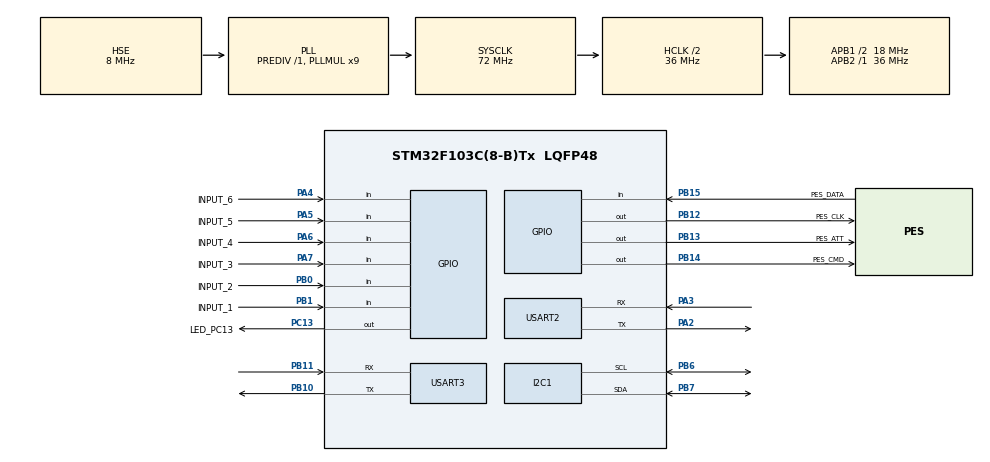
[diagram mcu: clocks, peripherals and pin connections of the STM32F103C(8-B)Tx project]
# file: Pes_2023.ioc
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IWDG.Prescaler=IWDG_PRESCALER_8
IWDG.Reload=2500-1
Mcu.Family=STM32F1
Mcu.Name=STM32F103C(8-B)Tx
Mcu.Package=LQFP48
NVIC.PriorityGroup=NVIC_PRIORITYGROUP_4
NVIC.USART3_IRQn=true\:0\:0\:false\:false\:true\:true\:true\:true
PA13.Mode=Serial_Wire
PA13.Signal=SYS_JTMS-SWDIO
PA14.Mode=Serial_Wire
PA14.Signal=SYS_JTCK-SWCLK
PA2.Mode=Asynchronous
PA2.Signal=USART2_TX
PA3.Mode=Asynchronous
PA3.Signal=USART2_RX
PA4.GPIO_Label=INPUT_6
PA4.GPIO_PuPd=GPIO_PULLUP
PA4.Signal=GPIO_Input
PA5.GPIO_Label=INPUT_5
PA5.GPIO_PuPd=GPIO_PULLUP
PA5.Signal=GPIO_Input
PA6.GPIO_Label=INPUT_4
PA6.GPIO_PuPd=GPIO_PULLUP
PA6.Signal=GPIO_Input
PA7.GPIO_Label=INPUT_3
PA7.GPIO_PuPd=GPIO_PULLUP
PA7.Signal=GPIO_Input
PB0.GPIO_Label=INPUT_2
PB0.GPIO_PuPd=GPIO_PULLUP
PB0.Signal=GPIO_Input
PB1.GPIO_Label=INPUT_1
PB1.GPIO_PuPd=GPIO_PULLUP
PB1.Signal=GPIO_Input
PB10.Mode=Asynchronous
PB10.Signal=USART3_TX
PB11.Mode=Asynchronous
PB11.Signal=USART3_RX
PB12.GPIO_Label=PES_CLK
PB12.GPIO_Speed=GPIO_SPEED_FREQ_MEDIUM
PB12.Signal=GPIO_Output
PB13.GPIO_Label=PES_ATT
PB13.GPIO_Speed=GPIO_SPEED_FREQ_MEDIUM
PB13.Signal=GPIO_Output
PB14.GPIO_Label=PES_CMD
PB14.GPIO_Speed=GPIO_SPEED_FREQ_MEDIUM
PB14.Signal=GPIO_Output
PB15.GPIO_Label=PES_DATA
PB15.GPIO_PuPd=GPIO_PULLUP
PB15.Signal=GPIO_Input
PB6.Mode=I2C
PB6.Signal=I2C1_SCL
PB7.Mode=I2C
PB7.Signal=I2C1_SDA
PC13-TAMPER-RTC.GPIO_Label=LED_PC13
PC13-TAMPER-RTC.Signal=GPIO_Output
PD0-OSC_IN.Mode=HSE-External-Oscillator
PD0-OSC_IN.Signal=RCC_OSC_IN
PD1-OSC_OUT.Mode=HSE-External-Oscillator
PD1-OSC_OUT.Signal=RCC_OSC_OUT
ProjectManager.HeapSize=0x200
ProjectManager.StackSize=0x400
ProjectManager.TargetToolchain=STM32CubeIDE
RCC.AHBCLKDivider=RCC_SYSCLK_DIV2
RCC.AHBFreq_Value=36000000
RCC.APB1CLKDivider=RCC_HCLK_DIV2
RCC.APB1Freq_Value=18000000
RCC.APB1TimFreq_Value=36000000
RCC.APB2Freq_Value=36000000
RCC.APB2TimFreq_Value=36000000
RCC.HCLKFreq_Value=36000000
RCC.PLLMUL=RCC_PLL_MUL9
RCC.PLLSourceVirtual=RCC_PLLSOURCE_HSE
RCC.SYSCLKFreq_VALUE=72000000
RCC.SYSCLKSource=RCC_SYSCLKSOURCE_PLLCLK
RCC.USBFreq_Value=72000000
USART2.VirtualMode=VM_ASYNC
USART3.VirtualMode=VM_ASYNC
VP_IWDG_VS_IWDG.Mode=IWDG_Activate
board=custom

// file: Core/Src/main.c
/* USER CODE BEGIN Header */
/**
  ******************************************************************************
  * @file           : main.c
  * @brief          : Main program body
  ******************************************************************************
  * @attention
  *
  * Copyright (c) 2023 STMicroelectronics.
  * All rights reserved.
  *
  * This software is licensed under terms that can be found in the LICENSE file
  * in the root directory of this software component.
  * If no LICENSE file comes with this software, it is provided AS-IS.
  *
  ******************************************************************************
  */
/* USER CODE END Header */
#include "main.h"

/* USER CODE BEGIN Includes */
#include "../user/main-app.h"
/* USER CODE END Includes */

I2C_HandleTypeDef hi2c1;

IWDG_HandleTypeDef hiwdg;

UART_HandleTypeDef huart2;
UART_HandleTypeDef huart3;

void SystemClock_Config(void);
static void MX_GPIO_Init(void);
static void MX_USART3_UART_Init(void);
static void MX_IWDG_Init(void);
static void MX_USART2_UART_Init(void);
static void MX_I2C1_Init(void);

int main(void)
{

  /* MCU Configuration--------------------------------------------------------*/

  /* Reset of all peripherals, Initializes the Flash interface and the Systick. */
  HAL_Init();

  /* Configure the system clock */
  SystemClock_Config();

  /* Initialize all configured peripherals */
  MX_GPIO_Init();
  MX_USART3_UART_Init();
  MX_IWDG_Init();
  MX_USART2_UART_Init();
  MX_I2C1_Init();
  /* USER CODE BEGIN 2 */
  main_Init();
  /* USER CODE END 2 */

  /* Infinite loop */
  /* USER CODE BEGIN WHILE */
  while (1)
  {
	  main_process();
	  HAL_IWDG_Refresh(&hiwdg);
    /* USER CODE END WHILE */

  }
}

void SystemClock_Config(void)
{
  RCC_OscInitTypeDef RCC_OscInitStruct = {0};
  RCC_ClkInitTypeDef RCC_ClkInitStruct = {0};

  /** Initializes the RCC Oscillators according to the specified parameters
  * in the RCC_OscInitTypeDef structure.
  */
  RCC_OscInitStruct.OscillatorType = RCC_OSCILLATORTYPE_LSI|RCC_OSCILLATORTYPE_HSE;
  RCC_OscInitStruct.HSEState = RCC_HSE_ON;
  RCC_OscInitStruct.HSEPredivValue = RCC_HSE_PREDIV_DIV1;
  RCC_OscInitStruct.HSIState = RCC_HSI_ON;
  RCC_OscInitStruct.LSIState = RCC_LSI_ON;
  RCC_OscInitStruct.PLL.PLLState = RCC_PLL_ON;
  RCC_OscInitStruct.PLL.PLLSource = RCC_PLLSOURCE_HSE;
  RCC_OscInitStruct.PLL.PLLMUL = RCC_PLL_MUL9;
  if (HAL_RCC_OscConfig(&RCC_OscInitStruct) != HAL_OK)
  {
    Error_Handler();
  }

  /** Initializes the CPU, AHB and APB buses clocks
  */
  RCC_ClkInitStruct.ClockType = RCC_CLOCKTYPE_HCLK|RCC_CLOCKTYPE_SYSCLK
                              |RCC_CLOCKTYPE_PCLK1|RCC_CLOCKTYPE_PCLK2;
  RCC_ClkInitStruct.SYSCLKSource = RCC_SYSCLKSOURCE_PLLCLK;
  RCC_ClkInitStruct.AHBCLKDivider = RCC_SYSCLK_DIV2;
  RCC_ClkInitStruct.APB1CLKDivider = RCC_HCLK_DIV2;
  RCC_ClkInitStruct.APB2CLKDivider = RCC_HCLK_DIV1;

  if (HAL_RCC_ClockConfig(&RCC_ClkInitStruct, FLASH_LATENCY_2) != HAL_OK)
  {
    Error_Handler();
  }
}

static void MX_I2C1_Init(void)
{

  hi2c1.Instance = I2C1;
  hi2c1.Init.ClockSpeed = 100000;
  hi2c1.Init.DutyCycle = I2C_DUTYCYCLE_2;
  hi2c1.Init.OwnAddress1 = 0;
  hi2c1.Init.AddressingMode = I2C_ADDRESSINGMODE_7BIT;
  hi2c1.Init.DualAddressMode = I2C_DUALADDRESS_DISABLE;
  hi2c1.Init.OwnAddress2 = 0;
  hi2c1.Init.GeneralCallMode = I2C_GENERALCALL_DISABLE;
  hi2c1.Init.NoStretchMode = I2C_NOSTRETCH_DISABLE;
  if (HAL_I2C_Init(&hi2c1) != HAL_OK)
  {
    Error_Handler();
  }

}

static void MX_IWDG_Init(void)
{

  hiwdg.Instance = IWDG;
  hiwdg.Init.Prescaler = IWDG_PRESCALER_8;
  hiwdg.Init.Reload = 2500-1;
  if (HAL_IWDG_Init(&hiwdg) != HAL_OK)
  {
    Error_Handler();
  }

}

static void MX_USART2_UART_Init(void)
{

  huart2.Instance = USART2;
  huart2.Init.BaudRate = 115200;
  huart2.Init.WordLength = UART_WORDLENGTH_8B;
  huart2.Init.StopBits = UART_STOPBITS_1;
  huart2.Init.Parity = UART_PARITY_NONE;
  huart2.Init.Mode = UART_MODE_TX_RX;
  huart2.Init.HwFlowCtl = UART_HWCONTROL_NONE;
  huart2.Init.OverSampling = UART_OVERSAMPLING_16;
  if (HAL_UART_Init(&huart2) != HAL_OK)
  {
    Error_Handler();
  }

}

static void MX_USART3_UART_Init(void)
{

  huart3.Instance = USART3;
  huart3.Init.BaudRate = 115200;
  huart3.Init.WordLength = UART_WORDLENGTH_8B;
  huart3.Init.StopBits = UART_STOPBITS_1;
  huart3.Init.Parity = UART_PARITY_NONE;
  huart3.Init.Mode = UART_MODE_TX_RX;
  huart3.Init.HwFlowCtl = UART_HWCONTROL_NONE;
  huart3.Init.OverSampling = UART_OVERSAMPLING_16;
  if (HAL_UART_Init(&huart3) != HAL_OK)
  {
    Error_Handler();
  }

}

static void MX_GPIO_Init(void)
{
  GPIO_InitTypeDef GPIO_InitStruct = {0};

  /* GPIO Ports Clock Enable */
  __HAL_RCC_GPIOC_CLK_ENABLE();
  __HAL_RCC_GPIOD_CLK_ENABLE();
  __HAL_RCC_GPIOA_CLK_ENABLE();
  __HAL_RCC_GPIOB_CLK_ENABLE();

  /*Configure GPIO pin Output Level */
  HAL_GPIO_WritePin(LED_PC13_GPIO_Port, LED_PC13_Pin, GPIO_PIN_RESET);

  /*Configure GPIO pin Output Level */
  HAL_GPIO_WritePin(GPIOB, PES_CLK_Pin|PES_ATT_Pin|PES_CMD_Pin, GPIO_PIN_RESET);

  /*Configure GPIO pin : LED_PC13_Pin */
  GPIO_InitStruct.Pin = LED_PC13_Pin;
  GPIO_InitStruct.Mode = GPIO_MODE_OUTPUT_PP;
  GPIO_InitStruct.Pull = GPIO_NOPULL;
  GPIO_InitStruct.Speed = GPIO_SPEED_FREQ_LOW;
  HAL_GPIO_Init(LED_PC13_GPIO_Port, &GPIO_InitStruct);

  /*Configure GPIO pins : INPUT_6_Pin INPUT_5_Pin INPUT_4_Pin INPUT_3_Pin */
  GPIO_InitStruct.Pin = INPUT_6_Pin|INPUT_5_Pin|INPUT_4_Pin|INPUT_3_Pin;
  GPIO_InitStruct.Mode = GPIO_MODE_INPUT;
  GPIO_InitStruct.Pull = GPIO_PULLUP;
  HAL_GPIO_Init(GPIOA, &GPIO_InitStruct);

  /*Configure GPIO pins : INPUT_2_Pin INPUT_1_Pin PES_DATA_Pin */
  GPIO_InitStruct.Pin = INPUT_2_Pin|INPUT_1_Pin|PES_DATA_Pin;
  GPIO_InitStruct.Mode = GPIO_MODE_INPUT;
  GPIO_InitStruct.Pull = GPIO_PULLUP;
  HAL_GPIO_Init(GPIOB, &GPIO_InitStruct);

  /*Configure GPIO pins : PES_CLK_Pin PES_ATT_Pin PES_CMD_Pin */
  GPIO_InitStruct.Pin = PES_CLK_Pin|PES_ATT_Pin|PES_CMD_Pin;
  GPIO_InitStruct.Mode = GPIO_MODE_OUTPUT_PP;
  GPIO_InitStruct.Pull = GPIO_NOPULL;
  GPIO_InitStruct.Speed = GPIO_SPEED_FREQ_MEDIUM;
  HAL_GPIO_Init(GPIOB, &GPIO_InitStruct);

}

void Error_Handler(void)
{
  __disable_irq();
  while (1)
  {
  }
}
